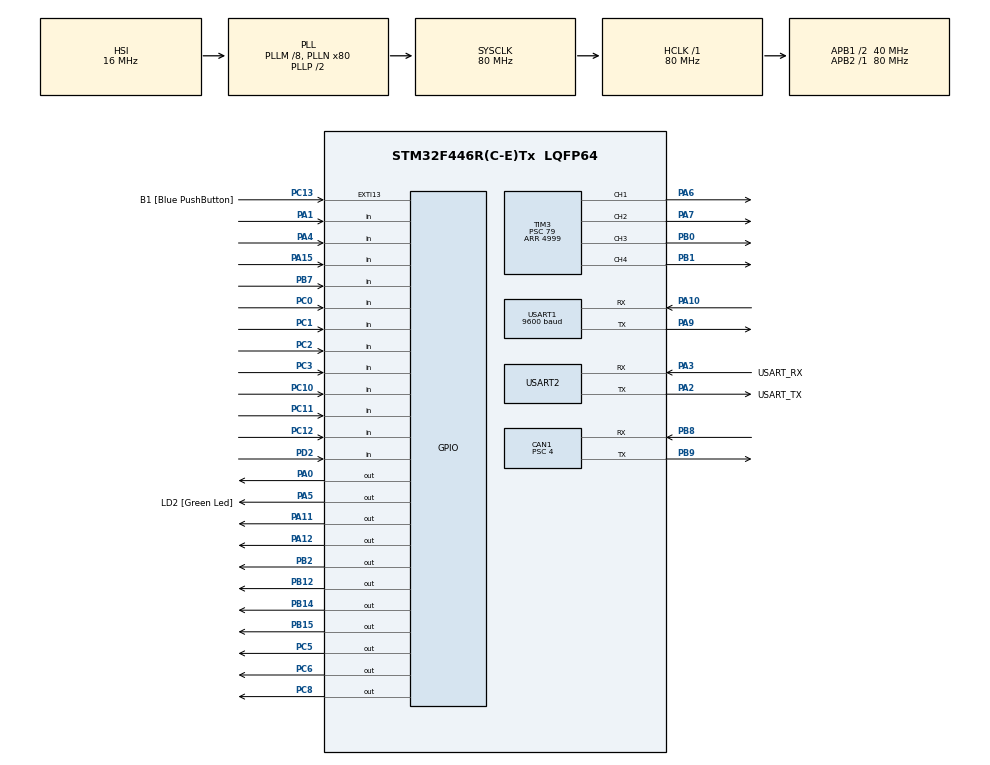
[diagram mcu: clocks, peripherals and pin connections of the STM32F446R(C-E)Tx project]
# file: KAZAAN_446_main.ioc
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CAN1.BS1=CAN_BS1_15TQ
CAN1.BS2=CAN_BS2_4TQ
CAN1.CalculateBaudRate=500000
CAN1.CalculateTimeBit=2000.00
CAN1.CalculateTimeQuantum=100.0
CAN1.Prescaler=4
Dma.Request0=USART1_RX
Dma.Request1=USART1_TX
Dma.Request2=USART2_RX
Dma.Request3=USART2_TX
Dma.USART1_RX.0.Direction=DMA_PERIPH_TO_MEMORY
Dma.USART1_RX.0.FIFOMode=DMA_FIFOMODE_DISABLE
Dma.USART1_RX.0.Instance=DMA2_Stream2
Dma.USART1_RX.0.MemDataAlignment=DMA_MDATAALIGN_BYTE
Dma.USART1_RX.0.MemInc=DMA_MINC_ENABLE
Dma.USART1_RX.0.Mode=DMA_NORMAL
Dma.USART1_RX.0.PeriphDataAlignment=DMA_PDATAALIGN_BYTE
Dma.USART1_RX.0.PeriphInc=DMA_PINC_DISABLE
Dma.USART1_RX.0.Priority=DMA_PRIORITY_LOW
Dma.USART1_TX.1.Direction=DMA_MEMORY_TO_PERIPH
Dma.USART1_TX.1.FIFOMode=DMA_FIFOMODE_DISABLE
Dma.USART1_TX.1.Instance=DMA2_Stream7
Dma.USART1_TX.1.MemDataAlignment=DMA_MDATAALIGN_BYTE
Dma.USART1_TX.1.MemInc=DMA_MINC_ENABLE
Dma.USART1_TX.1.Mode=DMA_NORMAL
Dma.USART1_TX.1.PeriphDataAlignment=DMA_PDATAALIGN_BYTE
Dma.USART1_TX.1.PeriphInc=DMA_PINC_DISABLE
Dma.USART1_TX.1.Priority=DMA_PRIORITY_LOW
Dma.USART2_RX.2.Direction=DMA_PERIPH_TO_MEMORY
Dma.USART2_RX.2.FIFOMode=DMA_FIFOMODE_DISABLE
Dma.USART2_RX.2.Instance=DMA1_Stream5
Dma.USART2_RX.2.MemDataAlignment=DMA_MDATAALIGN_BYTE
Dma.USART2_RX.2.MemInc=DMA_MINC_ENABLE
Dma.USART2_RX.2.Mode=DMA_NORMAL
Dma.USART2_RX.2.PeriphDataAlignment=DMA_PDATAALIGN_BYTE
Dma.USART2_RX.2.PeriphInc=DMA_PINC_DISABLE
Dma.USART2_RX.2.Priority=DMA_PRIORITY_LOW
Dma.USART2_TX.3.Direction=DMA_MEMORY_TO_PERIPH
Dma.USART2_TX.3.FIFOMode=DMA_FIFOMODE_DISABLE
Dma.USART2_TX.3.Instance=DMA1_Stream6
Dma.USART2_TX.3.MemDataAlignment=DMA_MDATAALIGN_BYTE
Dma.USART2_TX.3.MemInc=DMA_MINC_ENABLE
Dma.USART2_TX.3.Mode=DMA_NORMAL
Dma.USART2_TX.3.PeriphDataAlignment=DMA_PDATAALIGN_BYTE
Dma.USART2_TX.3.PeriphInc=DMA_PINC_DISABLE
Dma.USART2_TX.3.Priority=DMA_PRIORITY_LOW
Mcu.Family=STM32F4
Mcu.Name=STM32F446R(C-E)Tx
Mcu.Package=LQFP64
NVIC.CAN1_RX0_IRQn=true\:0\:0\:false\:false\:true\:true\:true
NVIC.CAN1_RX1_IRQn=true\:0\:0\:false\:false\:true\:true\:true
NVIC.CAN1_SCE_IRQn=true\:0\:0\:false\:false\:true\:true\:true
NVIC.CAN1_TX_IRQn=true\:0\:0\:false\:false\:true\:true\:true
NVIC.DMA1_Stream5_IRQn=true\:0\:0\:false\:false\:true\:false\:true
NVIC.DMA1_Stream6_IRQn=true\:0\:0\:false\:false\:true\:false\:true
NVIC.DMA2_Stream2_IRQn=true\:0\:0\:false\:false\:true\:false\:true
NVIC.DMA2_Stream7_IRQn=true\:0\:0\:false\:false\:true\:false\:true
NVIC.PriorityGroup=NVIC_PRIORITYGROUP_0
NVIC.USART1_IRQn=true\:0\:0\:false\:false\:true\:true\:true
NVIC.USART2_IRQn=true\:0\:0\:false\:false\:true\:true\:true
PA0-WKUP.GPIO_ModeDefaultOutputPP=GPIO_MODE_OUTPUT_OD
PA0-WKUP.Signal=GPIO_Output
PA1.GPIO_PuPd=GPIO_PULLUP
PA1.Signal=GPIO_Input
PA10.Mode=Asynchronous
PA10.Signal=USART1_RX
PA11.Signal=GPIO_Output
PA12.Signal=GPIO_Output
PA13.GPIO_Label=TMS
PA13.Mode=Serial_Wire
PA13.Signal=SYS_JTMS-SWDIO
PA14.GPIO_Label=TCK
PA14.Mode=Serial_Wire
PA14.Signal=SYS_JTCK-SWCLK
PA15.GPIO_PuPd=GPIO_PULLUP
PA15.Signal=GPIO_Input
PA2.GPIO_Label=USART_TX
PA2.Mode=Asynchronous
PA2.Signal=USART2_TX
PA3.GPIO_Label=USART_RX
PA3.Mode=Asynchronous
PA3.Signal=USART2_RX
PA4.GPIO_PuPd=GPIO_PULLUP
PA4.Signal=GPIO_Input
PA5.GPIO_Label=LD2 [Green Led]
PA5.Signal=GPIO_Output
PA6.Signal=S_TIM3_CH1
PA7.Signal=S_TIM3_CH2
PA9.Mode=Asynchronous
PA9.Signal=USART1_TX
PB0.Signal=S_TIM3_CH3
PB1.Signal=S_TIM3_CH4
PB12.Signal=GPIO_Output
PB14.Signal=GPIO_Output
PB15.Signal=GPIO_Output
PB2.Signal=GPIO_Output
PB3.GPIO_Label=SWO
PB3.Signal=SYS_JTDO-SWO
PB7.GPIO_PuPd=GPIO_PULLUP
PB7.Signal=GPIO_Input
PB8.Mode=CAN_Activate
PB8.Signal=CAN1_RX
PB9.Mode=CAN_Activate
PB9.Signal=CAN1_TX
PC0.GPIO_PuPd=GPIO_PULLUP
PC0.Signal=GPIO_Input
PC1.GPIO_PuPd=GPIO_PULLUP
PC1.Signal=GPIO_Input
PC10.GPIO_PuPd=GPIO_PULLUP
PC10.Signal=GPIO_Input
PC11.GPIO_PuPd=GPIO_PULLUP
PC11.Signal=GPIO_Input
PC12.GPIO_PuPd=GPIO_PULLUP
PC12.Signal=GPIO_Input
PC13.GPIO_Label=B1 [Blue PushButton]
PC13.GPIO_ModeDefaultEXTI=GPIO_MODE_IT_FALLING
PC13.Signal=GPXTI13
PC14-OSC32_IN.Mode=LSE-External-Oscillator
PC14-OSC32_IN.Signal=RCC_OSC32_IN
PC15-OSC32_OUT.Mode=LSE-External-Oscillator
PC15-OSC32_OUT.Signal=RCC_OSC32_OUT
PC2.GPIO_PuPd=GPIO_PULLUP
PC2.Signal=GPIO_Input
PC3.GPIO_PuPd=GPIO_PULLUP
PC3.Signal=GPIO_Input
PC5.Signal=GPIO_Output
PC6.Signal=GPIO_Output
PC8.Signal=GPIO_Output
PD2.GPIO_PuPd=GPIO_PULLUP
PD2.Signal=GPIO_Input
PH0-OSC_IN.Mode=HSE-External-Oscillator
PH0-OSC_IN.Signal=RCC_OSC_IN
PH1-OSC_OUT.Mode=HSE-External-Oscillator
PH1-OSC_OUT.Signal=RCC_OSC_OUT
ProjectManager.HeapSize=0x200
ProjectManager.StackSize=0x400
ProjectManager.TargetToolchain=STM32CubeIDE
RCC.48MHZClocksFreq_Value=84000000
RCC.AHBFreq_Value=80000000
RCC.APB1CLKDivider=RCC_HCLK_DIV2
RCC.APB1Freq_Value=40000000
RCC.APB1TimFreq_Value=80000000
RCC.APB2Freq_Value=80000000
RCC.APB2TimFreq_Value=80000000
RCC.CortexFreq_Value=80000000
RCC.FLatency-AdvancedSettings=FLASH_LATENCY_2
RCC.HCLKFreq_Value=80000000
RCC.HSE_VALUE=8000000
RCC.HSI_VALUE=16000000
RCC.PLLM=8
RCC.PLLN=80
RCC.SYSCLKFreq_VALUE=80000000
RCC.SYSCLKSource=RCC_SYSCLKSOURCE_PLLCLK
RCC.USBFreq_Value=80000000
RCC.VCOOutputFreq_Value=160000000
SH.S_TIM3_CH1.0=TIM3_CH1,PWM Generation1 CH1
SH.S_TIM3_CH2.0=TIM3_CH2,PWM Generation2 CH2
SH.S_TIM3_CH3.0=TIM3_CH3,PWM Generation3 CH3
SH.S_TIM3_CH4.0=TIM3_CH4,PWM Generation4 CH4
TIM3.Channel-PWM\ Generation1\ CH1=TIM_CHANNEL_1
TIM3.Channel-PWM\ Generation2\ CH2=TIM_CHANNEL_2
TIM3.Channel-PWM\ Generation3\ CH3=TIM_CHANNEL_3
TIM3.Channel-PWM\ Generation4\ CH4=TIM_CHANNEL_4
TIM3.Period=4999
TIM3.Prescaler=79
USART1.BaudRate=9600
USART1.VirtualMode=VM_ASYNC
USART2.VirtualMode=VM_ASYNC
VP_TIM3_VS_ClockSourceINT.Mode=Internal
board=NUCLEO-F446RE

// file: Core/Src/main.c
/* USER CODE BEGIN Header */
/**
  ******************************************************************************
  * @file           : main.c
  * @brief          : Main program body
  ******************************************************************************
  * @attention
  *
  * <h2><center>&copy; Copyright (c) 2023 STMicroelectronics.
  * All rights reserved.</center></h2>
  *
  * This software component is licensed by ST under BSD 3-Clause license,
  * the "License"; You may not use this file except in compliance with the
  * License. You may obtain a copy of the License at:
  *                        opensource.org/licenses/BSD-3-Clause
  *
  ******************************************************************************
  */
/* USER CODE END Header */
#include "main.h"

CAN_HandleTypeDef hcan1;

TIM_HandleTypeDef htim3;

UART_HandleTypeDef huart1;
UART_HandleTypeDef huart2;
DMA_HandleTypeDef hdma_usart1_rx;
DMA_HandleTypeDef hdma_usart1_tx;
DMA_HandleTypeDef hdma_usart2_rx;
DMA_HandleTypeDef hdma_usart2_tx;

/* USER CODE BEGIN PV */
volatile uint32_t G_System_counter = 0;
/* USER CODE END PV */

void SystemClock_Config(void);
static void MX_GPIO_Init(void);
static void MX_DMA_Init(void);
static void MX_USART1_UART_Init(void);
static void MX_USART2_UART_Init(void);
static void MX_TIM3_Init(void);
static void MX_CAN1_Init(void);

int main(void)
{

  /* MCU Configuration--------------------------------------------------------*/

  /* Reset of all peripherals, Initializes the Flash interface and the Systick. */
  HAL_Init();

  /* Configure the system clock */
  SystemClock_Config();

  /* Initialize all configured peripherals */
  MX_GPIO_Init();
  MX_DMA_Init();
  MX_USART1_UART_Init();
  MX_USART2_UART_Init();
  MX_TIM3_Init();
  MX_CAN1_Init();
  /* USER CODE BEGIN 2 */
  D_PWM_Init();
  D_CAN_Init();

  appInit();
  /* USER CODE END 2 */

  /* Infinite loop */
  /* USER CODE BEGIN WHILE */
  while (1)
  {
	  //メインタスクの処理
	  appTask();

	  //if(HAL_GPIO_ReadPin(GPIOC,GPIO_PIN_9) == 1){
		  //HAL_GPIO_WritePin(GPIOA,GPIO_PIN_5,GPIO_PIN_SET);
	  //}else if(HAL_GPIO_ReadPin(GPIOC,GPIO_PIN_9) == 0){
		  //HAL_GPIO_WritePin(GPIOA,GPIO_PIN_5,GPIO_PIN_RESET);
	  //}
	  /*if(HAL_GPIO_ReadPin(GPIOC,GPIO_PIN_13) == 0){
		  __HAL_TIM_SET_COMPARE(&htim3, TIM_CHANNEL_4, 50);
		  //__HAL_TIM_SET_COMPARE(&htim3, TIM_CHANNEL_2, 500);
		  HAL_GPIO_WritePin(GPIOC,GPIO_PIN_5,GPIO_PIN_SET);
		  //HAL_GPIO_WritePin(GPIOC,GPIO_PIN_6,GPIO_PIN_SET);
		  HAL_GPIO_WritePin(GPIOA,GPIO_PIN_5,GPIO_PIN_SET);

		  HAL_GPIO_WritePin(GPIOB,GPIO_PIN_14,GPIO_PIN_SET);
		  HAL_GPIO_WritePin(GPIOB,GPIO_PIN_15,GPIO_PIN_RESET);

		  D_Mess_printf("%d\n", G_System_counter);
		  D_Mess_flush();
	  }else if(HAL_GPIO_ReadPin(GPIOC,GPIO_PIN_13) == 1){
		  __HAL_TIM_SET_COMPARE(&htim3, TIM_CHANNEL_4, 2500);
		  //__HAL_TIM_SET_COMPARE(&htim3, TIM_CHANNEL_2, 100);
		  HAL_GPIO_WritePin(GPIOC,GPIO_PIN_5,GPIO_PIN_RESET);
		  HAL_GPIO_WritePin(GPIOC,GPIO_PIN_6,GPIO_PIN_RESET);
		  HAL_GPIO_WritePin(GPIOA,GPIO_PIN_5,GPIO_PIN_RESET);

		  HAL_GPIO_WritePin(GPIOB,GPIO_PIN_14,GPIO_PIN_RESET);
		  HAL_GPIO_WritePin(GPIOB,GPIO_PIN_15,GPIO_PIN_SET);
//		  D_Mess_printf("tes2");
//		  D_Mess_flush();
	  }*/
	  D_Mess_flush();
    /* USER CODE END WHILE */

  }
}

void SystemClock_Config(void)
{
  RCC_OscInitTypeDef RCC_OscInitStruct = {0};
  RCC_ClkInitTypeDef RCC_ClkInitStruct = {0};

  /** Configure the main internal regulator output voltage
  */
  __HAL_RCC_PWR_CLK_ENABLE();
  __HAL_PWR_VOLTAGESCALING_CONFIG(PWR_REGULATOR_VOLTAGE_SCALE3);
  /** Initializes the RCC Oscillators according to the specified parameters
  * in the RCC_OscInitTypeDef structure.
  */
  RCC_OscInitStruct.OscillatorType = RCC_OSCILLATORTYPE_HSI;
  RCC_OscInitStruct.HSIState = RCC_HSI_ON;
  RCC_OscInitStruct.HSICalibrationValue = RCC_HSICALIBRATION_DEFAULT;
  RCC_OscInitStruct.PLL.PLLState = RCC_PLL_ON;
  RCC_OscInitStruct.PLL.PLLSource = RCC_PLLSOURCE_HSI;
  RCC_OscInitStruct.PLL.PLLM = 8;
  RCC_OscInitStruct.PLL.PLLN = 80;
  RCC_OscInitStruct.PLL.PLLP = RCC_PLLP_DIV2;
  RCC_OscInitStruct.PLL.PLLQ = 2;
  RCC_OscInitStruct.PLL.PLLR = 2;
  if (HAL_RCC_OscConfig(&RCC_OscInitStruct) != HAL_OK)
  {
    Error_Handler();
  }
  /** Initializes the CPU, AHB and APB buses clocks
  */
  RCC_ClkInitStruct.ClockType = RCC_CLOCKTYPE_HCLK|RCC_CLOCKTYPE_SYSCLK
                              |RCC_CLOCKTYPE_PCLK1|RCC_CLOCKTYPE_PCLK2;
  RCC_ClkInitStruct.SYSCLKSource = RCC_SYSCLKSOURCE_PLLCLK;
  RCC_ClkInitStruct.AHBCLKDivider = RCC_SYSCLK_DIV1;
  RCC_ClkInitStruct.APB1CLKDivider = RCC_HCLK_DIV2;
  RCC_ClkInitStruct.APB2CLKDivider = RCC_HCLK_DIV1;

  if (HAL_RCC_ClockConfig(&RCC_ClkInitStruct, FLASH_LATENCY_2) != HAL_OK)
  {
    Error_Handler();
  }
}

static void MX_CAN1_Init(void)
{

  hcan1.Instance = CAN1;
  hcan1.Init.Prescaler = 4;
  hcan1.Init.Mode = CAN_MODE_NORMAL;
  hcan1.Init.SyncJumpWidth = CAN_SJW_1TQ;
  hcan1.Init.TimeSeg1 = CAN_BS1_15TQ;
  hcan1.Init.TimeSeg2 = CAN_BS2_4TQ;
  hcan1.Init.TimeTriggeredMode = DISABLE;
  hcan1.Init.AutoBusOff = DISABLE;
  hcan1.Init.AutoWakeUp = DISABLE;
  hcan1.Init.AutoRetransmission = DISABLE;
  hcan1.Init.ReceiveFifoLocked = DISABLE;
  hcan1.Init.TransmitFifoPriority = DISABLE;
  if (HAL_CAN_Init(&hcan1) != HAL_OK)
  {
    Error_Handler();
  }

}

static void MX_TIM3_Init(void)
{

  TIM_ClockConfigTypeDef sClockSourceConfig = {0};
  TIM_MasterConfigTypeDef sMasterConfig = {0};
  TIM_OC_InitTypeDef sConfigOC = {0};

  htim3.Instance = TIM3;
  htim3.Init.Prescaler = 79;
  htim3.Init.CounterMode = TIM_COUNTERMODE_UP;
  htim3.Init.Period = 4999;
  htim3.Init.ClockDivision = TIM_CLOCKDIVISION_DIV1;
  htim3.Init.AutoReloadPreload = TIM_AUTORELOAD_PRELOAD_DISABLE;
  if (HAL_TIM_Base_Init(&htim3) != HAL_OK)
  {
    Error_Handler();
  }
  sClockSourceConfig.ClockSource = TIM_CLOCKSOURCE_INTERNAL;
  if (HAL_TIM_ConfigClockSource(&htim3, &sClockSourceConfig) != HAL_OK)
  {
    Error_Handler();
  }
  if (HAL_TIM_PWM_Init(&htim3) != HAL_OK)
  {
    Error_Handler();
  }
  sMasterConfig.MasterOutputTrigger = TIM_TRGO_RESET;
  sMasterConfig.MasterSlaveMode = TIM_MASTERSLAVEMODE_DISABLE;
  if (HAL_TIMEx_MasterConfigSynchronization(&htim3, &sMasterConfig) != HAL_OK)
  {
    Error_Handler();
  }
  sConfigOC.OCMode = TIM_OCMODE_PWM1;
  sConfigOC.Pulse = 0;
  sConfigOC.OCPolarity = TIM_OCPOLARITY_HIGH;
  sConfigOC.OCFastMode = TIM_OCFAST_DISABLE;
  if (HAL_TIM_PWM_ConfigChannel(&htim3, &sConfigOC, TIM_CHANNEL_1) != HAL_OK)
  {
    Error_Handler();
  }
  if (HAL_TIM_PWM_ConfigChannel(&htim3, &sConfigOC, TIM_CHANNEL_2) != HAL_OK)
  {
    Error_Handler();
  }
  if (HAL_TIM_PWM_ConfigChannel(&htim3, &sConfigOC, TIM_CHANNEL_3) != HAL_OK)
  {
    Error_Handler();
  }
  if (HAL_TIM_PWM_ConfigChannel(&htim3, &sConfigOC, TIM_CHANNEL_4) != HAL_OK)
  {
    Error_Handler();
  }
  HAL_TIM_MspPostInit(&htim3);

}

static void MX_USART1_UART_Init(void)
{

  huart1.Instance = USART1;
  huart1.Init.BaudRate = 9600;
  huart1.Init.WordLength = UART_WORDLENGTH_8B;
  huart1.Init.StopBits = UART_STOPBITS_1;
  huart1.Init.Parity = UART_PARITY_NONE;
  huart1.Init.Mode = UART_MODE_TX_RX;
  huart1.Init.HwFlowCtl = UART_HWCONTROL_NONE;
  huart1.Init.OverSampling = UART_OVERSAMPLING_16;
  if (HAL_UART_Init(&huart1) != HAL_OK)
  {
    Error_Handler();
  }

}

static void MX_USART2_UART_Init(void)
{

  huart2.Instance = USART2;
  huart2.Init.BaudRate = 115200;
  huart2.Init.WordLength = UART_WORDLENGTH_8B;
  huart2.Init.StopBits = UART_STOPBITS_1;
  huart2.Init.Parity = UART_PARITY_NONE;
  huart2.Init.Mode = UART_MODE_TX_RX;
  huart2.Init.HwFlowCtl = UART_HWCONTROL_NONE;
  huart2.Init.OverSampling = UART_OVERSAMPLING_16;
  if (HAL_UART_Init(&huart2) != HAL_OK)
  {
    Error_Handler();
  }

}

static void MX_DMA_Init(void)
{

  /* DMA controller clock enable */
  __HAL_RCC_DMA2_CLK_ENABLE();
  __HAL_RCC_DMA1_CLK_ENABLE();

  /* DMA interrupt init */
  /* DMA1_Stream5_IRQn interrupt configuration */
  HAL_NVIC_SetPriority(DMA1_Stream5_IRQn, 0, 0);
  HAL_NVIC_EnableIRQ(DMA1_Stream5_IRQn);
  /* DMA1_Stream6_IRQn interrupt configuration */
  HAL_NVIC_SetPriority(DMA1_Stream6_IRQn, 0, 0);
  HAL_NVIC_EnableIRQ(DMA1_Stream6_IRQn);
  /* DMA2_Stream2_IRQn interrupt configuration */
  HAL_NVIC_SetPriority(DMA2_Stream2_IRQn, 0, 0);
  HAL_NVIC_EnableIRQ(DMA2_Stream2_IRQn);
  /* DMA2_Stream7_IRQn interrupt configuration */
  HAL_NVIC_SetPriority(DMA2_Stream7_IRQn, 0, 0);
  HAL_NVIC_EnableIRQ(DMA2_Stream7_IRQn);

}

static void MX_GPIO_Init(void)
{
  GPIO_InitTypeDef GPIO_InitStruct = {0};

  /* GPIO Ports Clock Enable */
  __HAL_RCC_GPIOC_CLK_ENABLE();
  __HAL_RCC_GPIOH_CLK_ENABLE();
  __HAL_RCC_GPIOA_CLK_ENABLE();
  __HAL_RCC_GPIOB_CLK_ENABLE();
  __HAL_RCC_GPIOD_CLK_ENABLE();

  /*Configure GPIO pin Output Level */
  HAL_GPIO_WritePin(GPIOA, GPIO_PIN_0|LD2_Pin|GPIO_PIN_11|GPIO_PIN_12, GPIO_PIN_RESET);

  /*Configure GPIO pin Output Level */
  HAL_GPIO_WritePin(GPIOC, GPIO_PIN_5|GPIO_PIN_6|GPIO_PIN_8, GPIO_PIN_RESET);

  /*Configure GPIO pin Output Level */
  HAL_GPIO_WritePin(GPIOB, GPIO_PIN_2|GPIO_PIN_12|GPIO_PIN_14|GPIO_PIN_15, GPIO_PIN_RESET);

  /*Configure GPIO pin : B1_Pin */
  GPIO_InitStruct.Pin = B1_Pin;
  GPIO_InitStruct.Mode = GPIO_MODE_IT_FALLING;
  GPIO_InitStruct.Pull = GPIO_NOPULL;
  HAL_GPIO_Init(B1_GPIO_Port, &GPIO_InitStruct);

  /*Configure GPIO pins : PC0 PC1 PC2 PC3
                           PC10 PC11 PC12 */
  GPIO_InitStruct.Pin = GPIO_PIN_0|GPIO_PIN_1|GPIO_PIN_2|GPIO_PIN_3
                          |GPIO_PIN_10|GPIO_PIN_11|GPIO_PIN_12;
  GPIO_InitStruct.Mode = GPIO_MODE_INPUT;
  GPIO_InitStruct.Pull = GPIO_PULLUP;
  HAL_GPIO_Init(GPIOC, &GPIO_InitStruct);

  /*Configure GPIO pin : PA0 */
  GPIO_InitStruct.Pin = GPIO_PIN_0;
  GPIO_InitStruct.Mode = GPIO_MODE_OUTPUT_OD;
  GPIO_InitStruct.Pull = GPIO_NOPULL;
  GPIO_InitStruct.Speed = GPIO_SPEED_FREQ_LOW;
  HAL_GPIO_Init(GPIOA, &GPIO_InitStruct);

  /*Configure GPIO pins : PA1 PA4 PA15 */
  GPIO_InitStruct.Pin = GPIO_PIN_1|GPIO_PIN_4|GPIO_PIN_15;
  GPIO_InitStruct.Mode = GPIO_MODE_INPUT;
  GPIO_InitStruct.Pull = GPIO_PULLUP;
  HAL_GPIO_Init(GPIOA, &GPIO_InitStruct);

  /*Configure GPIO pins : LD2_Pin PA11 PA12 */
  GPIO_InitStruct.Pin = LD2_Pin|GPIO_PIN_11|GPIO_PIN_12;
  GPIO_InitStruct.Mode = GPIO_MODE_OUTPUT_PP;
  GPIO_InitStruct.Pull = GPIO_NOPULL;
  GPIO_InitStruct.Speed = GPIO_SPEED_FREQ_LOW;
  HAL_GPIO_Init(GPIOA, &GPIO_InitStruct);

  /*Configure GPIO pins : PC5 PC6 PC8 */
  GPIO_InitStruct.Pin = GPIO_PIN_5|GPIO_PIN_6|GPIO_PIN_8;
  GPIO_InitStruct.Mode = GPIO_MODE_OUTPUT_PP;
  GPIO_InitStruct.Pull = GPIO_NOPULL;
  GPIO_InitStruct.Speed = GPIO_SPEED_FREQ_LOW;
  HAL_GPIO_Init(GPIOC, &GPIO_InitStruct);

  /*Configure GPIO pins : PB2 PB12 PB14 PB15 */
  GPIO_InitStruct.Pin = GPIO_PIN_2|GPIO_PIN_12|GPIO_PIN_14|GPIO_PIN_15;
  GPIO_InitStruct.Mode = GPIO_MODE_OUTPUT_PP;
  GPIO_InitStruct.Pull = GPIO_NOPULL;
  GPIO_InitStruct.Speed = GPIO_SPEED_FREQ_LOW;
  HAL_GPIO_Init(GPIOB, &GPIO_InitStruct);

  /*Configure GPIO pin : PD2 */
  GPIO_InitStruct.Pin = GPIO_PIN_2;
  GPIO_InitStruct.Mode = GPIO_MODE_INPUT;
  GPIO_InitStruct.Pull = GPIO_PULLUP;
  HAL_GPIO_Init(GPIOD, &GPIO_InitStruct);

  /*Configure GPIO pin : PB7 */
  GPIO_InitStruct.Pin = GPIO_PIN_7;
  GPIO_InitStruct.Mode = GPIO_MODE_INPUT;
  GPIO_InitStruct.Pull = GPIO_PULLUP;
  HAL_GPIO_Init(GPIOB, &GPIO_InitStruct);

}

/* USER CODE BEGIN 4 */
void HAL_UART_TxCpltCallback(UART_HandleTypeDef *UartHandle){
  UNUSED(UartHandle);
  if(UartHandle->Instance == USART2){
	  D_Mess_TransitionCompletedCallBack();
  }
}
void HAL_CAN_RxFifo0MsgPendingCallback(CAN_HandleTypeDef *hcan){
  D_CAN_ReceiveCallBack(hcan);
}
/*
void HAL_I2C_MasterTxCpltCallback(I2C_HandleTypeDef *hi2c){
  UNUSED(hi2c);
  if(hi2c->Instance == I2C1){
	  D_I2C1_TransitionCompletedCallBack();
  }
}
void HAL_I2C_MasterRxCpltCallback(I2C_HandleTypeDef *hi2c){
  UNUSED(hi2c);
  if(hi2c->Instance == I2C1){
	  D_I2C1_ReceptionCompletedCallBack();
  }
}
*/
/* USER CODE END 4 */

void Error_Handler(void)
{
  __disable_irq();
  while (1)
  {
  }
}

/************************ (C) COPYRIGHT STMicroelectronics *****END OF FILE****/
